# M3H2 register map
File version: 0.1
Registers are 32-bit, read-write, reset 0x0 unless marked. A register's access mark holds for its fields unless they carry their own. Offsets are from the block's base; [hi:lo] are bit positions; {n}, {i} and the like mark numbered series.

## PC — Port C
Base 0x400C0200
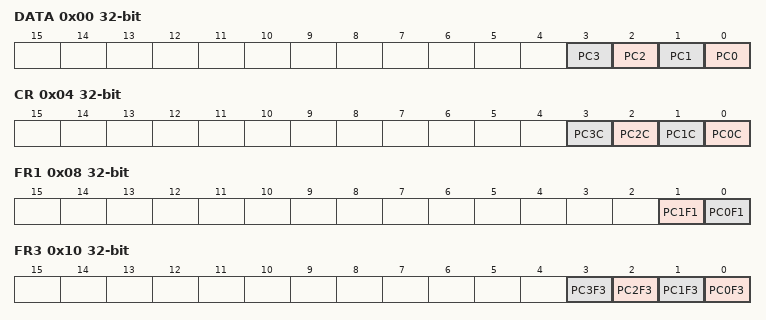
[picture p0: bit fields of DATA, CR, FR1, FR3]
0x00 DATA — PC Data Register
  [n] PC{n} (n=0..3)
0x04 CR — PC Control Register
  [n] PC{n}C (n=0..3)
0x08 FR1 — PC Function Register 1
  [1] PC1F1, [0] PC0F1
0x10 FR3 — PC Function Register 3
  [n] PC{n}F3 (n=0..3)
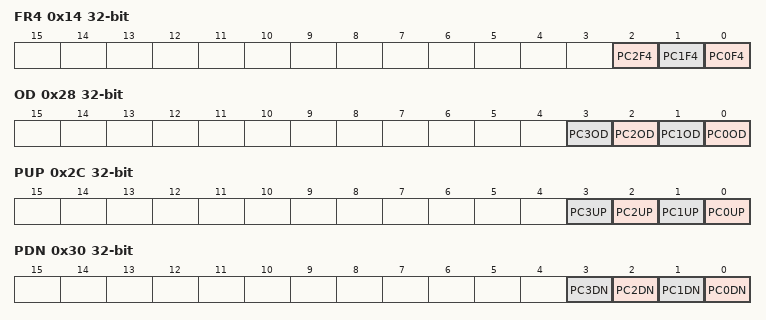
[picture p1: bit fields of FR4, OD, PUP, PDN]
0x14 FR4 — PC Function Register 4
  [2] PC2F4, [1] PC1F4, [0] PC0F4
0x18 FR5 — PC Function Register 5
  [2] PC2F5
0x28 OD — PC Open Drain Control Register
  [n] PC{n}OD (n=0..3)
0x2C PUP — PC Pull-up Control Register
  [n] PC{n}UP (n=0..3)
0x30 PDN — PC Pull-Down Control Register
  [n] PC{n}DN (n=0..3)
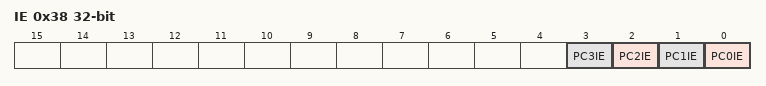
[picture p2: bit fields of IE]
0x38 IE — PC Input Enable Control Register
  [n] PC{n}IE (n=0..3)

## PD — Port D
Base 0x400C0300
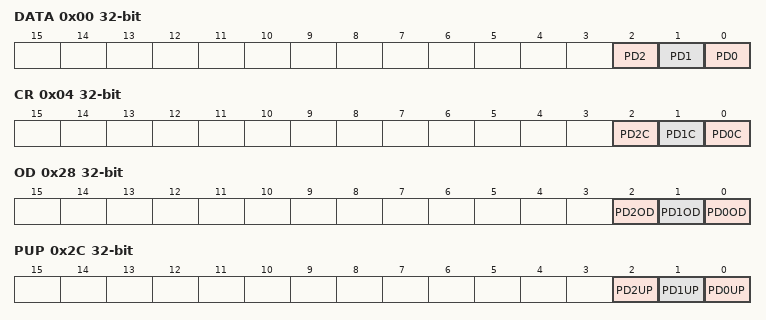
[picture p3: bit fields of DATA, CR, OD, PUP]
0x00 DATA — PD Data Register
  [2] PD2, [1] PD1, [0] PD0
0x04 CR — PD Control Register
  [2] PD2C, [1] PD1C, [0] PD0C
0x28 OD — PD Open Drain Control Register
  [2] PD2OD, [1] PD1OD, [0] PD0OD
0x2C PUP — PD Pull-up Control Register
  [2] PD2UP, [1] PD1UP, [0] PD0UP
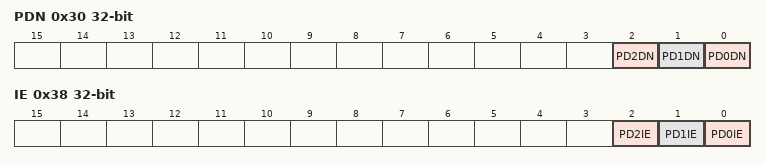
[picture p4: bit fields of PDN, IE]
0x30 PDN — PD Pull-Down Control Register
  [2] PD2DN, [1] PD1DN, [0] PD0DN
0x38 IE — PD Input Enable Control Register
  [2] PD2IE, [1] PD1IE, [0] PD0IE

## PE — Port E
Base 0x400C0400
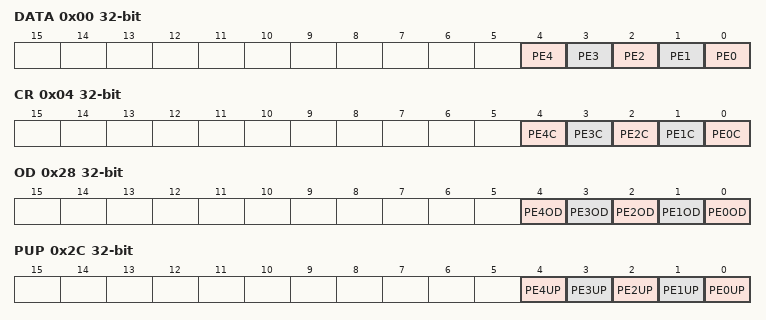
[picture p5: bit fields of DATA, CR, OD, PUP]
0x00 DATA — PE Data Register
  [n] PE{n} (n=0..4)
0x04 CR — PE Control Register
  [n] PE{n}C (n=0..4)
0x28 OD — PE Open Drain Control Register
  [n] PE{n}OD (n=0..4)
0x2C PUP — PE Pull-up Control Register
  [n] PE{n}UP (n=0..4)
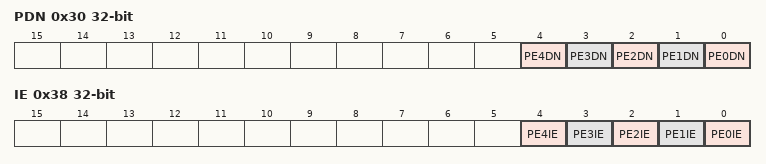
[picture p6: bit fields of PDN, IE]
0x30 PDN — PE Pull-Down Control Register
  [n] PE{n}DN (n=0..4)
0x38 IE — PE Input Enable Control Register
  [n] PE{n}IE (n=0..4)

## PG
Base 0x400C0600
0x00 DATA — PG Data Register
  [0] PG0
0x04 CR — PG Control Register
  [0] PG0C
0x28 OD — PG Open Drain Control Register
  [0] PG0OD
0x2C PUP — PG Pull-up Control Register
  [0] PG0UP
0x30 PDN — PG Pull-Down Control Register
  [0] PG0DN
0x38 IE — PG Input Enable Control Register
  [0] PG0IE

## PH
Base 0x400C0700
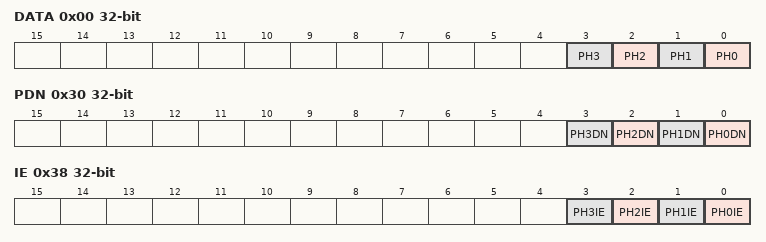
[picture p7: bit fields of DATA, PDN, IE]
0x00 DATA — PH Data Register
  [n] PH{n} (n=0..3)
0x30 PDN — PH Pull-Down Control Register
  [n] PH{n}DN (n=0..3)
0x38 IE — PH Input Enable Control Register
  [n] PH{n}IE (n=0..3)

## PJ
Base 0x400C0800
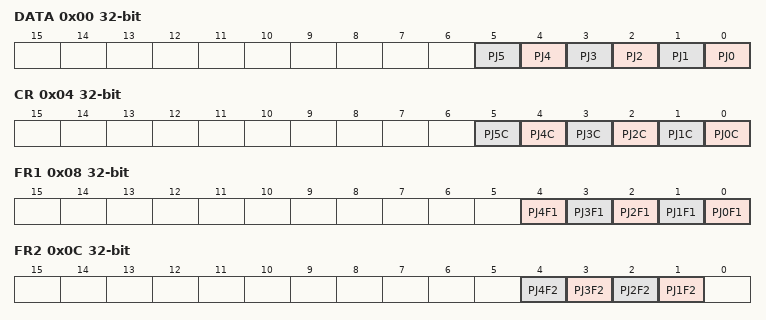
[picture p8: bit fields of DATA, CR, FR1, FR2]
0x00 DATA — PJ Data Register
  [n] PJ{n} (n=0..5)
0x04 CR — PJ Control Register
  [n] PJ{n}C (n=0..5)
0x08 FR1 — PJ Function Register 1
  [n] PJ{n}F1 (n=0..4)
0x0C FR2 — PJ Function Register 2
  [n] PJ{n}F2 (n=1..4)
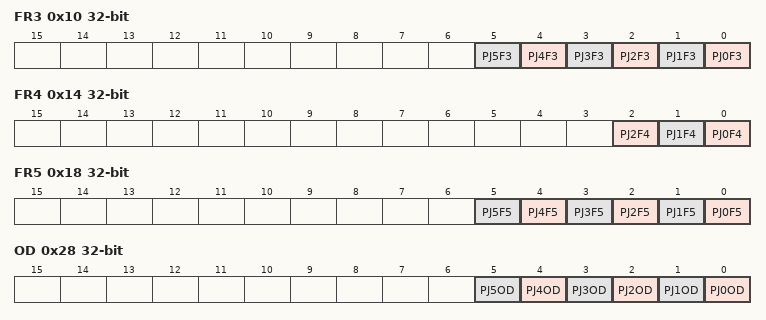
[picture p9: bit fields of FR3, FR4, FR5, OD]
0x10 FR3 — PJ Function Register 3
  [n] PJ{n}F3 (n=0..5)
0x14 FR4 — PJ Function Register 4
  [2] PJ2F4, [1] PJ1F4, [0] PJ0F4
0x18 FR5 — PJ Function Register 5
  [n] PJ{n}F5 (n=0..5)
0x28 OD — PJ Open Drain Control Register
  [n] PJ{n}OD (n=0..5)
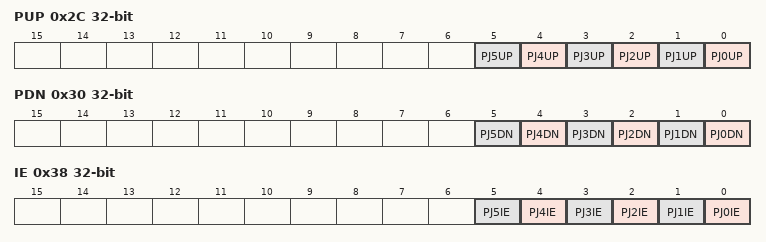
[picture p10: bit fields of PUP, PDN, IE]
0x2C PUP — PJ Pull-up Control Register
  [n] PJ{n}UP (n=0..5)
0x30 PDN — PJ Pull-Down Control Register
  [n] PJ{n}DN (n=0..5)
0x38 IE — PJ Input Enable Control Register
  [n] PJ{n}IE (n=0..5)

## PK
Base 0x400C0900
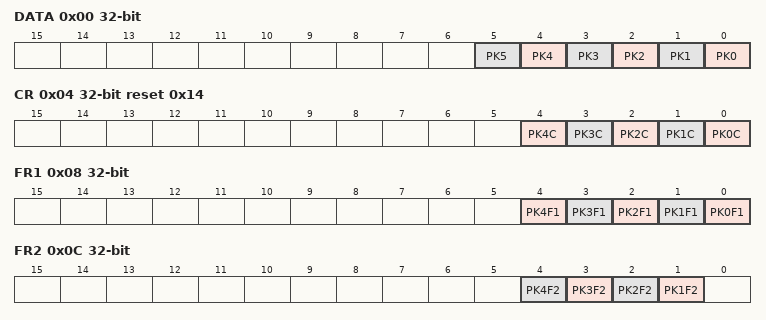
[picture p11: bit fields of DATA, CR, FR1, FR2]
0x00 DATA — PK Data Register
  [n] PK{n} (n=0..5)
0x04 CR reset 0x14 — PK Control Register
  [n] PK{n}C (n=0..4)
0x08 FR1 — PK Function Register 1
  [n] PK{n}F1 (n=0..4)
0x0C FR2 — PK Function Register 2
  [n] PK{n}F2 (n=1..4)
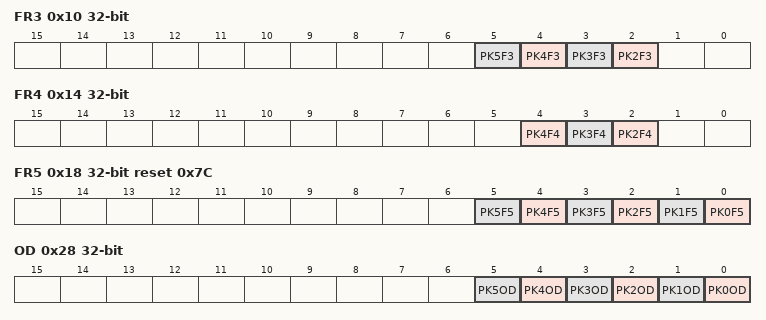
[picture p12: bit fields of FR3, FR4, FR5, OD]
0x10 FR3 — PK Function Register 3
  [n] PK{n}F3 (n=2..5)
0x14 FR4 — PK Function Register 4
  [4] PK4F4, [3] PK3F4, [2] PK2F4
0x18 FR5 reset 0x7C — PK Function Register 5
  [n] PK{n}F5 (n=0..5)
0x28 OD — PK Open Drain Control Register
  [n] PK{n}OD (n=0..5)
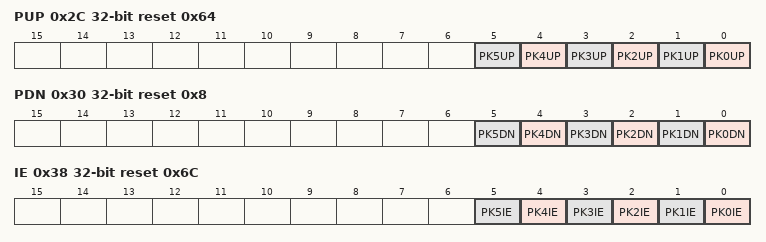
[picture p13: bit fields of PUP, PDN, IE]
0x2C PUP reset 0x64 — PK Pull-up Control Register
  [n] PK{n}UP (n=0..5)
0x30 PDN reset 0x8 — PK Pull-Down Control Register
  [n] PK{n}DN (n=0..5)
0x38 IE reset 0x6C — PK Input Enable Control Register
  [n] PK{n}IE (n=0..5)

## RTC
Base 0x400CC000
0x00 SECR 8-bit (reset mask 0x80) — RTC Sec setting register
  [6:0] SE
0x01 MINR 8-bit (reset mask 0x80) — RTC Min settging register
  [6:0] MI
0x02 HOURR 8-bit (reset mask 0xC0) — RTC Hour setting register
  [5:0] HO
0x04 DAYR 8-bit (reset mask 0xF8) — RTC Day setting register
  [2:0] WE
0x05 DATER 8-bit (reset mask 0xC0) — RTC Date setting register
  [5:0] DA
0x06 MONTHR_A 8-bit (reset mask 0xE0) — RTC Month settging register PAGE0
  [4:0] MO
0x06 MONTHR_B 8-bit (reset mask 0xFE) (RTC_MONTHR view) — RTC 24 hours _ 12 hours clock select register PAGE1
  [0] MO0
0x07 YEARR_A 8-bit reset not defined — RTC Year setting register PAGE0
  [7:0] YE
0x07 YEARR_B 8-bit (reset mask 0xFC) (RTC_YEARR view) — RTC Leap year register PAGE1
  [1:0] LEAP
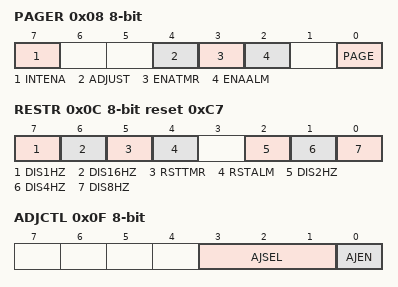
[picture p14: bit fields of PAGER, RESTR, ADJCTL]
0x08 PAGER 8-bit (reset mask 0xF3) — RTC Page register
  [7] INTENA, [4] ADJUST, [3] ENATMR, [2] ENAALM, [0] PAGE
0x0C RESTR 8-bit reset 0xC7 — RTC Reset register
  [7] DIS1HZ, [6] DIS16HZ, [5] RSTTMR, [4] RSTALM, [2] DIS2HZ, [1] DIS4HZ, [0] DIS8HZ
0x0E PROTECT 8-bit reset 0xC1 — RTC protect register
0x0F ADJCTL 8-bit (reset mask 0xF0) — RTC clock adjust control register
  [3:1] AJSEL, [0] AJEN
0x10 ADJDAT 8-bit reset not defined — RTC clock adjust data register
